# MDR_MLDR155 register map
Vendor: Milandr; Series: ARMCM4; File version: 2.0
CPU: CM4 r0p0, little endian, MPU, FPU, 3 interrupt priority bits
Registers are 32-bit, read-write, reset 0x0 unless marked. A register's access mark holds for its fields unless they carry their own. Offsets are from the block's base; [hi:lo] are bit positions; {n}, {i} and the like mark numbered series; 'fields as' and 'values as' point back to an identical list.

## MDR_BKP — Backup and RTC Control
Base 0x40001000
{0x0+4i} REG[{i}] (i=0..59) — User backup registers
0xF0 KEY — Unlock BKP and RTC Registers
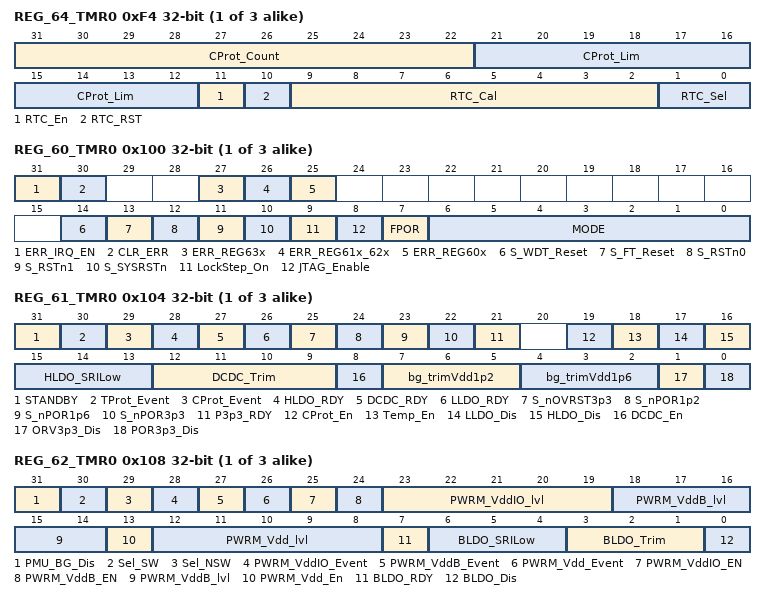
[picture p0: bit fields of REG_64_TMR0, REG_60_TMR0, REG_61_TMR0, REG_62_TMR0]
{0xF4+4i} REG_64_TMR{i} (i=0..2) — REG64 Control register
  [31:22] CProt_Count — Counter of I_Lim events
  [21:12] CProt_Lim — Current protection limit
  [11] RTC_En — RTC Enable
    0=Off (Disable); 1=On (Enable)
  [10] RTC_RST — RTC Reset
    0=Active (Enabled); 1=Reset (In Reset)
  [9:2] RTC_Cal — RTC pass counts
  [1:0] RTC_Sel — Select Clock for RTC
    0=LSI (LSI Clock); 1=LSE (LSE Clock); 2=RTCCLK (RTCCLK Clock)
{0x100+0x10*i} REG_60_TMR{i} (reset mask 0xE0007FFF) (i=0..2) — REG60 Control register
  [31] ERR_IRQ_EN — Enable BKP_IRQn on Errors
    0=Off (Disable); 1=On (Enable)
  [30] CLR_ERR — Clear Errors of REG_60x - 63x
    0=Inactive (Disable); 1=Clear Errors
  [27] ERR_REG63x — Fault in REG_63x
    0=Off (Event Inactive); 1=On (Event Active)
  [26] ERR_REG61x_62x — Fault in REG_61x or REG_62x
    0=Off (Event Inactive); 1=On (Event Active)
  [25] ERR_REG60x — Fault in REG_60x
    0=Off (Event Inactive); 1=On (Event Active)
  [14] S_WDT_Reset — Reset from WDT
    0=Off (Event Inactive); 1=On (Event Active)
  [13] S_FT_Reset — Reset from FT_CNTR
    0=Off (Event Inactive); 1=On (Event Active)
  [12] S_RSTn0 — Reset by RSTn0 signal
    0=Off (Event Inactive); 1=On (Event Active)
  [11] S_RSTn1 — Reset by RSTn1 signal
    0=Off (Event Inactive); 1=On (Event Active)
  [10] S_SYSRSTn — Reset by software
    0=Off (Event Inactive); 1=On (Event Active)
  [9] LockStep_On — Enable LockStep CPUs Mode
    0=Disable (Two independant CPUs); 1=Enable (LockStep CPUs)
  [8] JTAG_Enable — Disable JTAG
    0=On (Enabled); 1=Off (Disabled)
  [7] FPOR — Bootloader completed
    0=Bootloader active; 1=Completed (Bootloader completed)
  [6:0] MODE — Boot Mode
{0x104+0x10*i} REG_61_TMR{i} (i=0..2) — REG61 Control register
  [31] STANDBY — Go Standby mode
    0=Inactive (No Action); 1=GoStandby (Standby power off)
  [30] TProt_Event — Thermo is over
    0=Off (No Event); 1=On (Event active)
  [29] CProt_Event — CProt_cnt > CProt_lim
    0=Off (No Event); 1=On (Event active)
  [28] HLDO_RDY — DUcc 1.6V ready
    0=Off (Not Ready); 1=On (Ready)
  [27] DCDC_RDY — DCDC 1.6V ready
    0=Off (Not Ready); 1=On (Ready)
  [26] LLDO_RDY — DUcc 1.2V ready
    0=Off (Not Ready); 1=On (Ready)
  [25] S_nOVRST3p3 — Reset by Ucc > Uover
    0=Off (No Event); 1=On (Event active)
  [24] S_nPOR1p2 — Reset by DUcc_1.2V
    0=Off (No Event); 1=On (Event active)
  [23] S_nPOR1p6 — Reset by DUcc_1.6V
    0=Off (No Event); 1=On (Event active)
  [22] S_nPOR3p3 — Reset by DUcc_3.3V
    0=Off (No Event); 1=On (Event active)
  [21] P3p3_RDY — DUcc 3.3V ready
    0=Off (Not Ready); 1=On (Ready)
  [19] CProt_En — Current protection EN
    0=Off (Disable); 1=On (Enable)
  [18] Temp_En — Thermo protection EN
    0=Off (Disable); 1=On (Enable)
  [17] LLDO_Dis — LLDO Disable
    0=Enable state; 1=Disable state
  [16] HLDO_Dis — HLDO Disable
    0=Enable state; 1=Disable state
  [15:13] HLDO_SRILow — HLDO Power adjustment
    0=ge10MHz (Extra_I about ~300uA); 1=ge200KHz (Extra_I about ~7uA); 2=ge500KHz (Extra_I about ~20uA); 3=ge1MHz (Extra_I about ~80uA); 4=GensOff (Extra_I about ~2uA); 5=ge40MHz (Extra_I about ~900uA); 6=ge80MHz (Extra_I about ~5mA); 7=gt80MHz (Extra_I about ~20mA)
  [12:9] DCDC_Trim — DCDC 1.6V trim
    0=add_0v1 (LD0 extra voltage +0.1V); 1=add_0v06 (LD0 extra voltage +0.06V); 2=add_0v04 (LD0 extra voltage +0.04V); 3=add_0v01 (LD0 extra voltage +0.01V); 4=sub_0v01 (LD0 extra voltage -0.01V); 5=sub_0v04 (LD0 extra voltage -0.04V); 6=sub_0v06 (LD0 extra voltage -0.06V); 7=sub_0v1 (LD0 extra voltage -0.1V)
  [8] DCDC_En — Enable DCDC 1.6V
    0=Off (Disable); 1=On (Enable)
  [7:5] bg_trimVdd1p2 — DUcc 1.6V trim
    values as DCDC_Trim
  [4:2] bg_trimVdd1p6 — DUcc 1.6V trim
    values as DCDC_Trim
  [1] ORV3p3_Dis — Reset by Ucc > Uover
    0=Enable state; 1=Disable state
  [0] POR3p3_Dis — Reset by Ucc > Upor
    0=Enable state; 1=Disable state
{0x108+0x10*i} REG_62_TMR{i} (i=0..2) — REG62 Control register
  [31] PMU_BG_Dis — Disable PMU
    0=Enable state; 1=Disable state
  [30] Sel_SW — Select SW
    0=Off (Disable); 1=On (Enable)
  [29] Sel_NSW — Select NSW
    0=Off (Disable); 1=On (Enable)
  [28] PWRM_VddIO_Event — Vdd IO Event
    0=Off (No Event); 1=On (Event active)
  [27] PWRM_VddB_Event — Vdd BKP Event
    0=Off (No Event); 1=On (Event active)
  [26] PWRM_Vdd_Event — Vdd Event
    0=Off (No Event); 1=On (Event active)
  [25] PWRM_VddIO_EN — Vdd_IO monitor enable
    0=Off (Disable); 1=On (Enable)
  [24] PWRM_VddB_EN — Vdd_BKP monitor enable
    0=Off (Disable); 1=On (Enable)
  [23:19] PWRM_VddIO_lvl — Vdd_BKP 3.3V level
    {v}=lvl{v} (unknown level yet) (v=0..31)
  [18:14] PWRM_VddB_lvl — Vdd_BKP 3.3V level
    {v}=lvl{v} (unknown level yet) (v=0..31)
  [13] PWRM_Vdd_En — DCDC_3.3V monitor enable
    0=Off (Disable); 1=On (Enable)
  [12:8] PWRM_Vdd_lvl — DCDC_3.3V level
    {v}=lvl{v} (unknown level yet) (v=0..31)
  [7] BLDO_RDY — BLDO Ready
    0=Off (Disable); 1=On (Enable)
  [6:4] BLDO_SRILow — LDO_Bat Power adjustment
    values as REG_61_TMR0.HLDO_SRILow
  [3:1] BLDO_Trim — LDO_Bat Trim
    values as REG_61_TMR0.DCDC_Trim
  [0] BLDO_Dis — Disable LDO_Bat
    0=Enable state; 1=Disable state
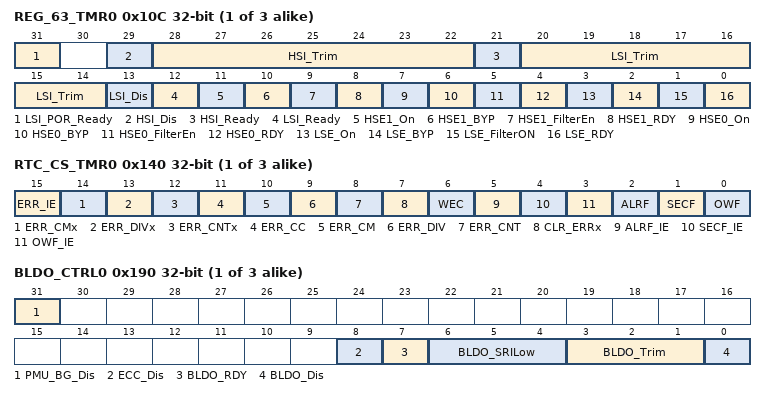
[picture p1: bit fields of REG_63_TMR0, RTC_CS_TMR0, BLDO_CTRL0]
{0x10C+0x10*i} REG_63_TMR{i} (i=0..2) — REG63 Control register
  [31] LSI_POR_Ready
    0=Off (Disable); 1=On (Enable)
  [29] HSI_Dis — HSI Disable
    0=Enable state; 1=Disable state
  [28:22] HSI_Trim — HSI freq trim
  [21] HSI_Ready
    0=Off (Disable); 1=On (Enable)
  [20:14] LSI_Trim — LSI freq trim
  [13] LSI_Dis — LSI Disable
    0=Enable state; 1=Disable state
  [12] LSI_Ready
    0=Off (Disable); 1=On (Enable)
  [11] HSE1_On — HSE1 Enable
    0=Off (Disable); 1=On (Enable)
  [10] HSE1_BYP — HSE1 Bypass
    0=Off (Disable); 1=On (Enable)
  [9] HSE1_FilterEn — HSE1 Filter enable
    0=Off (Disable); 1=On (Enable)
  [8] HSE1_RDY — HSE1 Ready
    0=Off (Disable); 1=On (Enable)
  [7] HSE0_On — HSE0 Enable
    0=Off (Disable); 1=On (Enable)
  [6] HSE0_BYP — HSE0 Bypass
    0=Off (Disable); 1=On (Enable)
  [5] HSE0_FilterEn — HSE0 Filter enable
    0=Off (Disable); 1=On (Enable)
  [4] HSE0_RDY — HSE0 Ready
    0=Off (Disable); 1=On (Enable)
  [3] LSE_On — LSE Enable
    0=Off (Disable); 1=On (Enable)
  [2] LSE_BYP — LSE Bypass
    0=Off (Disable); 1=On (Enable)
  [1] LSE_FilterON — LSE Input filter
    0=Off (Disable); 1=On (Enable)
  [0] LSE_RDY — LSE REady
    0=Off (Disable); 1=On (Enable)
{0x130+0x20*i} RTC_CNT_TMR{i} (i=0..2) — Count periods of PRL
{0x134+0x20*i} RTC_DIV_TMR{i} (i=0..2) — Counts RTC Clock to get PRL value
  [19:0] Value — RTC DIV value
{0x138+0x20*i} RTC_PRL_TMR{i} (i=0..2) — Period value for DIV counter
  [19:0] Value — RTC PRL value
{0x13C+0x20*i} RTC_ALRM_TMR{i} (i=0..2) — Event value for CNT counter
  [31:0] Value — Alarm value of CNT
{0x140+0x20*i} RTC_CS_TMR{i} (i=0..2) — RTC Control and Status
  [15] ERR_IE — Enable IRQ on RTC faults
    0=Off (Disable); 1=On (Enable)
  [14] ERR_CMx — Self channel clock fault
    0=Off (No event); 1=On (Event Active)
  [13] ERR_DIVx — Self channel DIV fault
    0=Off (No event); 1=On (Event Active)
  [12] ERR_CNTx — Self channel CNT fault
    0=Off (No event); 1=On (Event Active)
  [11] ERR_CC — Clock RTC too low
    0=Off (No event); 1=On (Event Active)
  [10] ERR_CM — Clock RTC too high
    0=Off (No event); 1=On (Event Active)
  [9] ERR_DIV — DIVx mistmatches
    0=Off (No event); 1=On (Event Active)
  [8] ERR_CNT — CNTx mistmatches
    0=Off (No event); 1=On (Event Active)
  [7] CLR_ERRx — Clear Errors
    0=Inactive (No Action); 1=Clear ERR_x Errors
  [6] WEC — RTC Busy flag
    0=Ready (Registers available); 1=Busy (Registers unavailable)
  [5] ALRF_IE — Enable IRQ by ALRF
    0=Off (No Event); 1=On (Event)
  [4] SECF_IE — Enable IRQ by SECF
    0=Off (No Event); 1=On (Event)
  [3] OWF_IE — Enable IRQ by OWF
    0=Off (No Event); 1=On (Event)
  [2] ALRF — CNT == ALRM Event, clear by set 1
    0=Off (No Event); 1=On (Event)
  [1] SECF — DIV == PRL Event, clear by set 1
    0=Off (No Event); 1=On (Event)
  [0] OWF — CNT Overflow flag, clear by set 1
    0=Off (No Event); 1=On (Event)
{0x190+4i} BLDO_CTRL{i} (reset mask 0x8000001FF) (i=0..2) — Battery LDO Control
  [31] PMU_BG_Dis — Disable PMU
    0=Enable state; 1=Disable state
  [8] ECC_Dis — Disable ECC
    0=Enable state; 1=Disable state
  [7] BLDO_RDY — BLDO Ready
    0=Off (Enable); 1=On (Disable)
  [6:4] BLDO_SRILow — LDO_Bat Power adjustment
    values as REG_61_TMR0.HLDO_SRILow
  [3:1] BLDO_Trim — LDO_Bat Trim
    values as REG_61_TMR0.DCDC_Trim
  [0] BLDO_Dis — Disable Battery LDO
    0=Enable state; 1=Disable state
